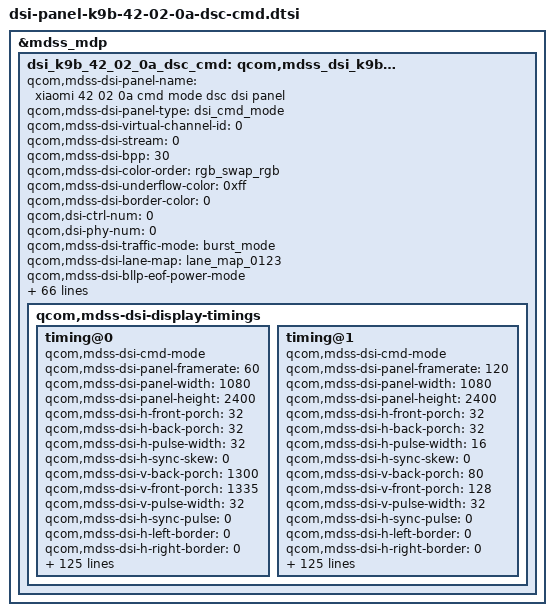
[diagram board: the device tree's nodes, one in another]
&mdss_mdp {
	dsi_k9b_42_02_0a_dsc_cmd: qcom,mdss_dsi_k9b_42_02_0a_dsc_cmd {
		qcom,mdss-dsi-panel-name = "xiaomi 42 02 0a cmd mode dsc dsi panel";
		qcom,mdss-dsi-panel-type = "dsi_cmd_mode";
		qcom,mdss-dsi-virtual-channel-id = <0>;
		qcom,mdss-dsi-stream = <0>;
		qcom,mdss-dsi-bpp = <30>;
		qcom,mdss-dsi-color-order = "rgb_swap_rgb";
		qcom,mdss-dsi-underflow-color = <0xff>;
		qcom,mdss-dsi-border-color = <0>;

		qcom,dsi-ctrl-num = <0>;
		qcom,dsi-phy-num = <0>;

		qcom,mdss-dsi-traffic-mode = "burst_mode";
		qcom,mdss-dsi-lane-map = "lane_map_0123";
		qcom,mdss-dsi-bllp-eof-power-mode;
		qcom,mdss-dsi-bllp-power-mode;
		qcom,mdss-dsi-lane-0-state;
		qcom,mdss-dsi-lane-1-state;
		qcom,mdss-dsi-lane-2-state;
		qcom,mdss-dsi-lane-3-state;
		qcom,mdss-dsi-dma-trigger = "trigger_sw";
		qcom,mdss-dsi-mdp-trigger = "none";
		qcom,mdss-dsi-reset-sequence =  <1 11>, <0 1>, <1 11>;
		qcom,mdss-pan-physical-width-dimension = <683>;
		qcom,mdss-pan-physical-height-dimension = <1517>;
		qcom,mdss-dsi-te-pin-select = <1>;
		qcom,mdss-dsi-wr-mem-start = <0x2c>;
		qcom,mdss-dsi-wr-mem-continue = <0x3c>;
		qcom,mdss-dsi-te-dcs-command = <1>;
		qcom,mdss-dsi-te-check-enable;
		qcom,mdss-dsi-te-using-te-pin;
		qcom,mdss-dsi-tx-eot-append;
		qcom,mdss-dsi-lp11-init;

		qcom,mdss-dsi-bl-inverted-dbv;
		qcom,bl-update-flag = "delay_until_first_frame";
		qcom,mdss-dsi-panel-mode-switch;

		qcom,mdss-dsi-panel-hdr-enabled;
		qcom,mdss-dsi-panel-hdr-color-primaries = <14500 15500 32000 17000 15500 30000 8000 3000>;
		qcom,mdss-dsi-panel-peak-brightness = <4200000>;
		qcom,mdss-dsi-panel-blackness-level = <3230>;

		qcom,mdss-dsi-display-timings {
			timing@0{
				qcom,mdss-dsi-cmd-mode;
				qcom,mdss-dsi-panel-framerate = <60>;
				qcom,mdss-dsi-panel-width = <1080>;
				qcom,mdss-dsi-panel-height = <2400>;
				qcom,mdss-dsi-h-front-porch = <32>;
				qcom,mdss-dsi-h-back-porch = <32>;
				qcom,mdss-dsi-h-pulse-width = <32>;
				qcom,mdss-dsi-h-sync-skew = <0>;
				qcom,mdss-dsi-v-back-porch = <1300>;
				qcom,mdss-dsi-v-front-porch = <1335>;
				qcom,mdss-dsi-v-pulse-width = <32>;
				qcom,mdss-dsi-h-sync-pulse = <0>;
				qcom,mdss-dsi-h-left-border = <0>;
				qcom,mdss-dsi-h-right-border = <0>;
				qcom,mdss-dsi-v-top-border = <0>;
				qcom,mdss-dsi-v-bottom-border = <0>;
				qcom,mdss-dsi-panel-clockrate = <831000000>;
				qcom,mdss-dsi-panel-jitter = <0x5 0x1>;
				qcom,mdss-mdp-transfer-time-us = <14000>;
				qcom,mdss-dsi-on-command = [
					/* DSC Setting */
					15 01 00 00 00 00 02 90 01
					39 01 00 00 00 00 13 91
						A9 28 00 0C C2 00 03 1C 01 7E 00 0F 08 BB 04 3D
						10 F0
					15 01 00 00 00 00 02 03 01
					05 01 00 00 00 00 02 2C 00
					/* TE ON Setting */
					15 01 00 00 00 00 02 35 00
					/* CASET/RASET Setting */
					39 01 00 00 00 00 05 2A 00 00 04 37 /* CASET 1080 */
					39 01 00 00 00 00 05 2B 00 00 09 5F /* PASET 2400 */
					/* Dimming OFF Setting */
					15 01 00 00 00 00 02 53 20
					/* dimming 8 frame */
					39 01 00 00 00 00 06 F0 55 AA 52 08 00
					39 00 00 00 00 00 02 6F 02
					39 01 00 00 00 00 03 B2 08 08
					/* Brightness Setting Normal */
					39 01 00 00 00 00 03 51 00 00
					/* Frame Rate 60Hz */
					15 01 00 00 00 00 02 2F 01
					/* MIPI Speed = 831Mbps @osc 127.9525Mhz */
					39 01 00 00 00 00 06 F0 55 AA 52 08 01
					39 00 00 00 00 00 08 C3 94 01 8C D0 22 02 00
					39 00 00 00 00 00 02 6F 01
					39 00 00 00 00 00 04 D2 00 00 11
					39 00 00 00 00 00 02 6F 06
					39 00 00 00 00 00 02 D2 05
					//U_ELVDD discharge
					39 00 00 00 00 00 02 6F 09
					39 00 00 00 00 00 03 D2 00 00
					39 00 00 00 00 00 02 6F 0F
					39 00 00 00 00 00 02 D2 00
					// U_ELVDD/U_ELVSS FD disable , AVDD FD disable
					39 00 00 00 00 00 02 CE 00
					//cmd3: aod no black
					39 01 00 00 00 00 05 FF AA 55 A5 80
					39 00 00 00 00 00 02 6F 61
					39 00 00 00 00 00 02 F3 80
					/* Page 0 */
					39 01 00 00 00 00 06 F0 55 AA 52 08 00
					39 00 00 00 00 00 02 C0 46
					//esd normal high without mipi error
					39 00 00 00 00 00 03 BE 0E 0B
					39 00 00 00 00 00 02 6F 05
					39 00 00 00 00 00 02 BE 88
					//PMIC normal FD en
					39 00 00 00 00 00 02 6F 08
					39 00 00 00 00 00 02 B5 32
					//PMIC AOD FD disable
					39 00 00 00 00 00 02 6F 0B
					39 00 00 00 00 00 04 B5 33 23 2B
					/* local hbm */
					39 00 00 00 00 00 02 6F 29
					39 00 00 00 00 00 02 D9 00
					39 00 00 00 00 00 02 6F 01
					39 00 00 00 00 00 02 D9 80
					39 00 00 00 00 00 02 6F 07
					39 00 00 00 00 00 03 B2 07 FF
					39 00 00 00 00 00 02 6F 17
					39 00 00 00 00 00 03 B2 07 FF
					39 00 00 00 00 00 02 6F 1F
					39 01 00 00 00 00 03 B2 00 50
					39 01 00 00 00 00 06 F0 55 AA 52 08 07
					39 00 00 00 00 00 02 C0 05
					39 00 00 00 00 00 2C C1 30 0F 03 C1 0B D1 F2 AE 3F FC DC AA 3F F9 27 4A 80 00 A7 E2 79 00 1A 00 00 85 1F 33 B0 0C F5 0F E1 95 00 00 00 14 18 00 19 1F 00
					39 00 00 00 00 00 2C C2 38 0F 0D 99 02 71 F4 7A 3F F9 F8 D6 FF FD E2 02 00 00 75 80 91 00 00 20 00 19 8F 33 F0 0A D7 0F 91 E7 00 00 04 1E 18 04 23 1F 00
					39 00 00 00 00 00 2C C3 36 00 03 C1 0B D1 0D 52 00 00 00 00 3F F3 96 04 80 00 00 00 00 03 B2 00 04 1D 1F 33 B0 00 00 03 1F 95 00 00 90 14 40 90 19 47 00
					39 00 00 00 00 00 2C C4 3E 00 0D 99 02 71 0B 86 00 03 5F 48 FF FC C1 EC 00 00 00 00 00 04 1E 20 04 37 8F 33 F0 00 00 03 6F E7 00 00 94 1E 40 94 23 47 00
					39 00 00 00 00 00 2C C5 2C 00 0D 99 02 71 0B 86 3F F4 F9 BC C0 00 00 00 00 00 00 00 00 80 00 D0 90 19 3F 33 F0 00 00 0C 91 19 00 00 00 00 00 00 00 00 00
					39 00 00 00 00 00 2C C6 2C 00 03 C1 0B D1 0D 52 3F FB 3F BC 00 03 FC 18 00 00 00 00 00 90 1A 40 90 85 5F 33 30 00 00 0C E1 6B 00 00 00 00 00 00 00 00 00
					39 00 00 00 00 00 2C C7 2A 0F 03 C1 0B D1 F2 AE 00 01 9C EE 00 09 8D 5E 7F FE AB 86 0D 93 B2 40 94 1D 5F 33 3F F3 0B 00 1F 6B 00 00 00 00 00 00 00 00 00
					39 01 00 00 00 00 2C C8 2A 0F 0D 99 02 71 F4 7A 00 08 5E 62 C0 01 20 16 7F FF 0D 95 E5 84 1E D0 94 37 3F 33 FF F5 29 00 6F 19 00 00 00 00 00 00 00 00 00
					39 00 00 00 00 00 2C C9 21 00 2A 40 2B E4 00 00 3F DD 03 00 3F DC 56 C0 80 07 3E 61 00 71 B3 FA 82 1D 62 33 F0 2B 10 0F 98 96 00 00 00 00 00 00 00 00 00
					39 00 00 00 00 00 2C CA 27 00 2B 11 28 A4 00 00 00 00 00 00 3F DE A9 78 80 00 00 00 00 72 1E FA 82 84 63 33 D0 00 00 03 69 9A 00 00 00 00 00 00 00 00 00
					39 00 00 00 00 00 2C CB 2D 00 2A 40 2B 11 00 00 3F DD 57 80 80 00 00 00 00 00 00 00 00 81 B3 63 82 1C CB 33 90 00 00 0C 98 69 00 00 00 00 00 00 00 00 00
					39 00 00 00 00 00 2C CC 2B 00 29 71 29 71 00 00 00 00 00 00 80 00 00 00 7F F9 4A 9C 1F 82 1D 64 82 84 CB 33 8F D6 8F 00 67 67 00 00 00 00 00 00 00 00 00
					39 00 00 00 00 00 2C CD 2D 00 03 C1 03 C1 00 00 3F FF 17 42 00 00 00 00 80 00 00 00 00 01 FC 3F 02 1B 5E 33 50 00 00 0C E1 1F 00 00 00 00 00 00 00 00 00
					39 00 00 00 00 00 2C CE 2B 00 03 C1 03 C1 00 00 00 00 00 00 00 00 00 00 FF FF F1 E8 7F 02 1C 3F 02 3B 5E 33 5F FC 3F 00 1F 1F 00 00 00 00 00 00 00 00 00
					39 00 00 00 00 00 2C CF 21 00 03 C1 03 84 00 00 3F FF 1E C4 3F FF 26 08 00 00 0D 32 84 01 FC 1F 02 1A 3E 33 80 03 A2 0F E1 E2 00 00 00 00 00 00 00 00 00
					39 01 00 00 00 00 2C D0 27 00 03 C1 04 00 00 00 00 00 00 00 3F FF 08 00 00 00 00 00 00 02 1B 1F 02 3B 3E 33 90 00 00 03 1F E0 00 00 00 00 00 00 00 00 00
					/* Sleep Out */
					05 01 00 00 50 00 02 11 00
					/* Display On */
					05 01 00 00 00 00 02 29 00];
				qcom,mdss-dsi-off-command = [
					05 01 00 00 14 00 02 28 00
					05 01 00 00 50 00 02 10 00];
				qcom,mdss-dsi-on-command-state = "dsi_lp_mode";
				qcom,mdss-dsi-off-command-state = "dsi_lp_mode";

				qcom,mdss-dsi-timing-switch-command = [
					15 01 00 00 10 00 02 2F 01
				];
				qcom,mdss-dsi-timing-switch-command-state = "dsi_hs_mode";

				qcom,mdss-dsi-lp1-command = [
					/* Frame Rate 60Hz AOD on*/
					15 01 00 00 00 00 02 2F 01
					39 00 00 00 00 00 06 F0 55 AA 52 08 08
					39 00 00 00 00 00 02 6F 07
					39 01 00 00 00 00 05 B9 00 00 00 24
					39 01 00 00 00 00 06 F0 55 AA 52 08 00
					39 00 00 00 00 00 02 B2 08
					39 00 00 00 00 00 02 39 00
					39 01 00 00 00 00 02 65 01
				];
				qcom,mdss-dsi-lp1-commandd-state = "dsi_hs_mode";

				qcom,mdss-dsi-nolp-command = [
					39 01 00 00 00 00 06 F0 55 AA 52 08 01
					39 00 00 00 00 00 02 6F 02
					39 01 00 00 00 00 02 D2 03
					39 01 00 00 00 00 06 F0 55 AA 52 08 00
					39 00 00 00 00 00 02 B2 18
					39 00 00 00 00 00 02 65 00
					39 01 00 00 00 00 02 38 00
				];
				qcom,mdss-dsi-nolp-command-state = "dsi_hs_mode";

				qcom,compression-mode = "dsc";
				qcom,mdss-dsc-version = <0x11>;
				qcom,mdss-dsc-scr-version = <0x0>;
				qcom,mdss-dsc-slice-height = <12>;
				qcom,mdss-dsc-slice-width = <1080>;
				qcom,mdss-dsc-slice-per-pkt = <1>;
				qcom,mdss-dsc-bit-per-component = <10>;
				qcom,mdss-dsc-bit-per-pixel = <8>;
				qcom,mdss-dsc-block-prediction-enable;
			};
			timing@1{
				qcom,mdss-dsi-cmd-mode;
				qcom,mdss-dsi-panel-framerate = <120>;
				qcom,mdss-dsi-panel-width = <1080>;
				qcom,mdss-dsi-panel-height = <2400>;
				qcom,mdss-dsi-h-front-porch = <32>;
				qcom,mdss-dsi-h-back-porch = <32>;
				qcom,mdss-dsi-h-pulse-width = <16>;
				qcom,mdss-dsi-h-sync-skew = <0>;
				qcom,mdss-dsi-v-back-porch = <80>;
				qcom,mdss-dsi-v-front-porch = <128>;
				qcom,mdss-dsi-v-pulse-width = <32>;
				qcom,mdss-dsi-h-sync-pulse = <0>;
				qcom,mdss-dsi-h-left-border = <0>;
				qcom,mdss-dsi-h-right-border = <0>;
				qcom,mdss-dsi-v-top-border = <0>;
				qcom,mdss-dsi-v-bottom-border = <0>;
				qcom,mdss-dsi-panel-clockrate = <831000000>;
				qcom,mdss-dsi-panel-jitter = <0x5 0x1>;
				qcom,mdss-mdp-transfer-time-us = <8000>;
				qcom,mdss-dsi-on-command = [
					/* DSC Setting */
					15 01 00 00 00 00 02 90 01
					39 01 00 00 00 00 13 91
						A9 28 00 0C C2 00 03 1C 01 7E 00 0F 08 BB 04 3D
						10 F0
					15 01 00 00 00 00 02 03 01
					05 01 00 00 00 00 02 2C 00
					/* TE ON Setting */
					15 01 00 00 00 00 02 35 00
					/* CASET/RASET Setting */
					39 01 00 00 00 00 05 2A 00 00 04 37 /* CASET 1080 */
					39 01 00 00 00 00 05 2B 00 00 09 5F /* PASET 2400 */
					/* Dimming Off seting */
					15 01 00 00 00 00 02 53 20
					/* dimming 8 frame */
					39 01 00 00 00 00 06 F0 55 AA 52 08 00
					39 00 00 00 00 00 02 6F 02
					39 01 00 00 00 00 03 B2 08 08
					/* Brightness Setting Normal */
					39 01 00 00 00 00 03 51 00 00
					/* Frame Rate 120Hz */
					15 01 00 00 00 00 02 2F 02
					/* MIPI Speed = 831Mbps @osc 127.9525Mhz */
					39 01 00 00 00 00 06 F0 55 AA 52 08 01
					39 00 00 00 00 00 08 C3 94 01 8C D0 22 02 00
					39 00 00 00 00 00 02 6F 01
					39 00 00 00 00 00 04 D2 00 00 11
					39 00 00 00 00 00 02 6F 06
					39 00 00 00 00 00 02 D2 05
					//U_ELVDD discharge
					39 00 00 00 00 00 02 6F 09
					39 00 00 00 00 00 03 D2 00 00
					39 00 00 00 00 00 02 6F 0F
					39 00 00 00 00 00 02 D2 00
					// U_ELVDD/U_ELVSS FD disable , AVDD FD disable
					39 00 00 00 00 00 02 CE 00
					//cmd3: aod no black
					39 01 00 00 00 00 05 FF AA 55 A5 80
					39 00 00 00 00 00 02 6F 61
					39 00 00 00 00 00 02 F3 80
					/* Page 0 */
					39 01 00 00 00 00 06 F0 55 AA 52 08 00
					39 00 00 00 00 00 02 C0 46
					//esd normal high without mipi error
					39 00 00 00 00 00 03 BE 0E 0B
					39 00 00 00 00 00 02 6F 05
					39 00 00 00 00 00 02 BE 88
					//PMIC normal FD en
					39 00 00 00 00 00 02 6F 08
					39 00 00 00 00 00 02 B5 32
					//PMIC AOD FD disable
					39 00 00 00 00 00 02 6F 0B
					39 00 00 00 00 00 04 B5 33 23 2B
					/* local hbm */
					39 00 00 00 00 00 02 6F 29
					39 00 00 00 00 00 02 D9 00
					39 00 00 00 00 00 02 6F 01
					39 00 00 00 00 00 02 D9 80
					39 00 00 00 00 00 02 6F 07
					39 00 00 00 00 00 03 B2 07 FF
					39 00 00 00 00 00 02 6F 17
					39 00 00 00 00 00 03 B2 07 FF
					39 00 00 00 00 00 02 6F 1F
					39 01 00 00 00 00 03 B2 00 50
					39 01 00 00 00 00 06 F0 55 AA 52 08 07
					39 00 00 00 00 00 02 C0 05
					39 00 00 00 00 00 2C C1 30 0F 03 C1 0B D1 F2 AE 3F FC DC AA 3F F9 27 4A 80 00 A7 E2 79 00 1A 00 00 85 1F 33 B0 0C F5 0F E1 95 00 00 00 14 18 00 19 1F 00
					39 00 00 00 00 00 2C C2 38 0F 0D 99 02 71 F4 7A 3F F9 F8 D6 FF FD E2 02 00 00 75 80 91 00 00 20 00 19 8F 33 F0 0A D7 0F 91 E7 00 00 04 1E 18 04 23 1F 00
					39 00 00 00 00 00 2C C3 36 00 03 C1 0B D1 0D 52 00 00 00 00 3F F3 96 04 80 00 00 00 00 03 B2 00 04 1D 1F 33 B0 00 00 03 1F 95 00 00 90 14 40 90 19 47 00
					39 00 00 00 00 00 2C C4 3E 00 0D 99 02 71 0B 86 00 03 5F 48 FF FC C1 EC 00 00 00 00 00 04 1E 20 04 37 8F 33 F0 00 00 03 6F E7 00 00 94 1E 40 94 23 47 00
					39 00 00 00 00 00 2C C5 2C 00 0D 99 02 71 0B 86 3F F4 F9 BC C0 00 00 00 00 00 00 00 00 80 00 D0 90 19 3F 33 F0 00 00 0C 91 19 00 00 00 00 00 00 00 00 00
					39 00 00 00 00 00 2C C6 2C 00 03 C1 0B D1 0D 52 3F FB 3F BC 00 03 FC 18 00 00 00 00 00 90 1A 40 90 85 5F 33 30 00 00 0C E1 6B 00 00 00 00 00 00 00 00 00
					39 00 00 00 00 00 2C C7 2A 0F 03 C1 0B D1 F2 AE 00 01 9C EE 00 09 8D 5E 7F FE AB 86 0D 93 B2 40 94 1D 5F 33 3F F3 0B 00 1F 6B 00 00 00 00 00 00 00 00 00
					39 01 00 00 00 00 2C C8 2A 0F 0D 99 02 71 F4 7A 00 08 5E 62 C0 01 20 16 7F FF 0D 95 E5 84 1E D0 94 37 3F 33 FF F5 29 00 6F 19 00 00 00 00 00 00 00 00 00
					39 00 00 00 00 00 2C C9 21 00 2A 40 2B E4 00 00 3F DD 03 00 3F DC 56 C0 80 07 3E 61 00 71 B3 FA 82 1D 62 33 F0 2B 10 0F 98 96 00 00 00 00 00 00 00 00 00
					39 00 00 00 00 00 2C CA 27 00 2B 11 28 A4 00 00 00 00 00 00 3F DE A9 78 80 00 00 00 00 72 1E FA 82 84 63 33 D0 00 00 03 69 9A 00 00 00 00 00 00 00 00 00
					39 00 00 00 00 00 2C CB 2D 00 2A 40 2B 11 00 00 3F DD 57 80 80 00 00 00 00 00 00 00 00 81 B3 63 82 1C CB 33 90 00 00 0C 98 69 00 00 00 00 00 00 00 00 00
					39 00 00 00 00 00 2C CC 2B 00 29 71 29 71 00 00 00 00 00 00 80 00 00 00 7F F9 4A 9C 1F 82 1D 64 82 84 CB 33 8F D6 8F 00 67 67 00 00 00 00 00 00 00 00 00
					39 00 00 00 00 00 2C CD 2D 00 03 C1 03 C1 00 00 3F FF 17 42 00 00 00 00 80 00 00 00 00 01 FC 3F 02 1B 5E 33 50 00 00 0C E1 1F 00 00 00 00 00 00 00 00 00
					39 00 00 00 00 00 2C CE 2B 00 03 C1 03 C1 00 00 00 00 00 00 00 00 00 00 FF FF F1 E8 7F 02 1C 3F 02 3B 5E 33 5F FC 3F 00 1F 1F 00 00 00 00 00 00 00 00 00
					39 00 00 00 00 00 2C CF 21 00 03 C1 03 84 00 00 3F FF 1E C4 3F FF 26 08 00 00 0D 32 84 01 FC 1F 02 1A 3E 33 80 03 A2 0F E1 E2 00 00 00 00 00 00 00 00 00
					39 01 00 00 00 00 2C D0 27 00 03 C1 04 00 00 00 00 00 00 00 3F FF 08 00 00 00 00 00 00 02 1B 1F 02 3B 3E 33 90 00 00 03 1F E0 00 00 00 00 00 00 00 00 00
					/* Sleep Out */
					05 01 00 00 50 00 02 11 00
					/* Display On */
					05 01 00 00 00 00 02 29 00];
				qcom,mdss-dsi-off-command = [
					05 01 00 00 14 00 02 28 00
					05 01 00 00 50 00 02 10 00];
				qcom,mdss-dsi-on-command-state = "dsi_lp_mode";
				qcom,mdss-dsi-off-command-state = "dsi_lp_mode";

				qcom,mdss-dsi-timing-switch-command = [
					15 01 00 00 10 00 02 2F 02
				];
				qcom,mdss-dsi-timing-switch-command-state = "dsi_hs_mode";

				qcom,mdss-dsi-lp1-command = [
					/* Frame Rate 120Hz AOD on*/
					15 01 00 00 00 00 02 2F 01
					39 00 00 00 00 00 06 F0 55 AA 52 08 08
					39 00 00 00 00 00 02 6F 07
					39 01 00 00 00 00 05 B9 00 00 00 24
					39 01 00 00 00 00 06 F0 55 AA 52 08 00
					39 00 00 00 00 00 02 B2 08
					39 00 00 00 00 00 02 39 00
					39 01 00 00 00 00 02 65 01
				];
				qcom,mdss-dsi-lp1-commandd-state = "dsi_hs_mode";

				qcom,mdss-dsi-nolp-command = [
					39 01 00 00 00 00 06 F0 55 AA 52 08 01
					39 00 00 00 00 00 02 6F 02
					39 01 00 00 00 00 02 D2 03
					/* AOD off */
					39 01 00 00 00 00 06 F0 55 AA 52 08 00
					39 00 00 00 00 00 02 B2 18
					39 00 00 00 00 00 02 65 00
					39 01 00 00 00 00 02 38 00
					39 01 00 00 00 00 02 2F 02
				];
				qcom,mdss-dsi-nolp-command-state = "dsi_hs_mode";

				qcom,compression-mode = "dsc";
				qcom,mdss-dsc-version = <0x11>;
				qcom,mdss-dsc-scr-version = <0x0>;
				qcom,mdss-dsc-slice-height = <12>;
				qcom,mdss-dsc-slice-width = <1080>;
				qcom,mdss-dsc-slice-per-pkt = <1>;
				qcom,mdss-dsc-bit-per-component = <10>;
				qcom,mdss-dsc-bit-per-pixel = <8>;
				qcom,mdss-dsc-block-prediction-enable;
			};
		};
	};
};

&dsi_k9b_42_02_0a_dsc_cmd {
	mi,panel-id = <0x004B3942 0x00420200>;
	mi,hbm-51-ctl-flag;
	mi,bl-51ctl-32bit-flag;
	mi,aod-bl-51ctl-flag;
	mi,aod-brightness = <0x155 0x0FFF>;
	mi,hbm-off-51-index = <0>;
	mi,hbm-fod-off-51-index = <1>;
	mi,hbm-bl-min-level = <1>;
	mi,hbm-bl-max-level = <2047>;
	mi,max-brightness-clone = <4095>;
	mi,thermal-dimming-flag;

	mi,local-hbm-enabled;
	mi,local-hbm-off-to-hbm-51-index = <1>;
	mi,local-hbm-off-to-normal-51-index = <1>;
	mi,local-hbm-on-87-index = <5>;
	mi,local-hbm-hlpm-on-87-index = <10>;
	mi,doze-hbm-dbv-level = <245>;
	mi,doze-lbm-dbv-level = <20>;
	mi,fod-low-brightness-clone-threshold = <38>;
	mi,fod-low-brightness-lux-threshold = <1>;

	mi,flatmode-update-flag;
	mi,flatmode-on-b9-index = <3>;

	mi,lhbm-update-flag;

	/* IRQF_ONESHOT | IRQF_TRIGGER_FALLING */
	mi,esd-err-irq-gpio = <&tlmm 3 0x2002>;

	mi,panel-aod-to-off-command-need-enabled;

	mi,panel-on-dimming-delay = <120>;

	qcom,esd-check-enabled;
	qcom,esd-aod-check-enabled;
	qcom,mdss-dsi-panel-status-check-mode = "reg_read";
	qcom,mdss-dsi-panel-status-offset-command = [
		39 01 00 00 00 00 05 FF AA 55 A5 81
		15 01 00 00 00 00 02 6F 0F];
	qcom,mdss-dsi-panel-status-command = [06 01 00 00 00 00 01 FA];
	qcom,mdss-dsi-panel-status-command-state = "dsi_lp_mode";
	qcom,mdss-dsi-panel-status-offset-command-state = "dsi_lp_mode";
	qcom,mdss-dsi-panel-status-value = <0x00>;
	qcom,mdss-dsi-panel-status-read-length = <1>;

	qcom,mdss-dsi-display-timings {
		timing@0{ /* 60hz */
			mi,mdss-dsc-panel-id = <0x004B3942 0x00420200>;
			mi,mdss-dsi-dimmingon-command = [15 01 00 00 00 00 02 53 28];
			mi,mdss-dsi-dimmingon-command-state = "dsi_hs_mode";
			mi,mdss-dsi-dimmingoff-command = [15 01 00 00 00 00 02 53 20];
			mi,mdss-dsi-dimmingoff-command-state = "dsi_hs_mode";

			mi,mdss-dsi-hbm-on-command = [39 01 00 00 00 00 03 51 0F FF];
			mi,mdss-dsi-hbm-on-command-state = "dsi_hs_mode";
			mi,mdss-dsi-hbm-off-command = [39 01 00 00 00 00 03 51 07 FF];
			mi,mdss-dsi-hbm-off-command-state = "dsi_hs_mode";

			mi,mdss-dsi-doze-hbm-command = [
				39 01 00 00 00 00 06 F0 55 AA 52 08 00
				39 00 00 00 00 00 02 B2 08
				39 00 00 00 00 00 05 51 00 F5 0F FF
				39 00 00 00 00 00 02 39 00
				39 01 00 00 00 00 02 65 01
			];
			mi,mdss-dsi-doze-hbm-command-state = "dsi_hs_mode";
			mi,mdss-dsi-doze-lbm-command = [
				39 01 00 00 00 00 06 F0 55 AA 52 08 00
				39 00 00 00 00 00 02 B2 08
				39 00 00 00 00 00 05 51 00 14 01 55
				39 00 00 00 00 00 02 39 00
				39 01 00 00 00 00 02 65 01
			];
			mi,mdss-dsi-doze-lbm-command-state = "dsi_hs_mode";

			mi,mdss-dsi-doze-hbm-nolp-command = [
				/* AOD off */
				39 01 00 00 00 00 06 F0 55 AA 52 08 00
				39 00 00 00 00 00 02 B2 18
				39 00 00 00 00 00 05 51 00 F5 0F FF
				39 00 00 00 00 00 02 65 00
				39 01 00 00 07 00 02 38 00
				39 01 00 00 00 00 06 F0 55 AA 52 08 01
				39 01 00 00 1B 00 05 BA 10 1A 10 1A
				39 01 00 00 00 00 05 BA 10 10 10 10
			];
			mi,mdss-dsi-doze-hbm-nolp-command-state = "dsi_hs_mode";
			mi,mdss-dsi-doze-lbm-nolp-command = [
				/* AOD off */
				39 01 00 00 00 00 06 F0 55 AA 52 08 00
				39 00 00 00 00 00 02 B2 18
				39 00 00 00 00 00 05 51 00 14 01 55
				39 00 00 00 00 00 02 65 00
				39 01 00 00 07 00 02 38 00
				39 01 00 00 00 00 06 F0 55 AA 52 08 01
				39 01 00 00 1B 00 05 BA 10 1A 10 1A
				39 01 00 00 00 00 05 BA 10 10 10 10
			];
			mi,mdss-dsi-doze-lbm-nolp-command-state = "dsi_hs_mode";

			mi,mdss-dsi-hbm-fod-on-command = [
				15 01 00 00 00 00 02 53 20
				39 00 00 00 00 00 03 51 0F FF
				39 00 00 00 00 00 02 6F 02
				39 01 00 00 00 00 02 87 04
			];
			mi,mdss-dsi-hbm-fod-on-command-state = "dsi_hs_mode";
			mi,mdss-dsi-hbm-fod-off-command = [
				15 01 00 00 00 00 02 53 20
				39 00 00 00 00 00 03 51 07 FF
				39 00 00 00 00 00 02 6F 02
				39 01 00 00 00 00 02 87 04
			];
			mi,mdss-dsi-hbm-fod-off-command-state = "dsi_hs_mode";

			mi,mdss-dsi-local-hbm-normal-white-1000nit-command = [
				39 01 00 00 00 00 06 F0 55 AA 52 08 02
				39 00 00 00 00 00 02 6F 08
				39 00 00 00 00 00 07 D0 0B 07 09 7B 0C 1D
				39 00 00 00 00 00 02 53 20
				39 00 00 00 00 00 05 88 02 1C 08 63
				39 00 00 00 00 00 03 87 0F FF
				39 00 00 00 00 00 03 51 07 FF
				39 00 00 00 00 00 02 6F 02
				39 01 00 00 21 00 02 87 05
			];
			mi,mdss-dsi-local-hbm-normal-white-1000nit-command-state = "dsi_hs_mode";

			mi,mdss-dsi-local-hbm-hlpm-white-1000nit-command = [
				/* AOD off */
				39 01 00 00 00 00 06 F0 55 AA 52 08 00
				39 00 00 00 00 00 02 B2 18
				39 00 00 00 00 00 02 65 00
				39 01 00 00 22 00 02 38 00
				/* 60HZ */
				15 01 00 00 00 00 02 2F 01
				/* Local HBM setting*/
				39 00 00 00 00 00 06 F0 55 AA 52 08 02
				39 00 00 00 00 00 02 6F 08
				39 00 00 00 00 00 07 D0 0B 07 09 7B 0C 1D
				39 00 00 00 00 00 02 53 20
				39 00 00 00 00 00 05 88 02 1C 08 63
				39 00 00 00 00 00 03 87 0F FF
				39 00 00 00 00 00 03 51 07 FF
				39 00 00 00 00 00 02 6F 02
				39 01 00 00 21 00 02 87 05
			];
			mi,mdss-dsi-local-hbm-hlpm-white-1000nit-command-state = "dsi_hs_mode";

			mi,mdss-dsi-local-hbm-normal-white-110nit-command = [
				39 01 00 00 00 00 06 F0 55 AA 52 08 02
				39 00 00 00 00 00 02 6F 08
				39 00 00 00 00 00 07 D0 07 62 06 74 07 F7
				39 00 00 00 00 00 02 53 20
				39 00 00 00 00 00 05 88 02 1C 08 63
				39 00 00 00 00 00 03 87 0F FF
				39 00 00 00 00 00 03 51 07 FF
				39 00 00 00 00 00 02 6F 02
				39 01 00 00 21 00 02 87 05
			];
			mi,mdss-dsi-local-hbm-normal-white-110nit-command-state = "dsi_hs_mode";

			mi,mdss-dsi-local-hbm-hlpm-white-110nit-command = [
				/* AOD off */
				39 01 00 00 00 00 06 F0 55 AA 52 08 00
				39 00 00 00 00 00 02 B2 18
				39 00 00 00 00 00 02 65 00
				39 01 00 00 22 00 02 38 00
				/* 60HZ */
				15 01 00 00 00 00 02 2F 01
				/* Local HBM setting*/
				39 01 00 00 00 00 06 F0 55 AA 52 08 02
				39 00 00 00 00 00 02 6F 08
				39 00 00 00 00 00 07 D0 07 62 06 74 07 F7
				39 00 00 00 00 00 02 53 20
				39 00 00 00 00 00 05 88 02 1C 08 63
				39 00 00 00 00 00 03 87 0F FF
				39 00 00 00 00 00 03 51 07 FF
				39 00 00 00 00 00 02 6F 02
				39 01 00 00 21 00 02 87 05
			];
			mi,mdss-dsi-local-hbm-hlpm-white-110nit-command-state = "dsi_hs_mode";

			mi,mdss-dsi-local-hbm-normal-green-500nit-command = [
				39 01 00 00 00 00 06 F0 55 AA 52 08 02
				39 00 00 00 00 00 02 6F 08
				39 00 00 00 00 00 07 D0 00 00 09 40 00 00
				39 00 00 00 00 00 02 53 20
				39 00 00 00 00 00 05 88 02 1C 08 63
				39 00 00 00 00 00 03 87 0F FF
				39 00 00 00 00 00 03 51 07 FF
				39 00 00 00 00 00 02 6F 02
				39 01 00 00 21 00 02 87 05
			];
			mi,mdss-dsi-local-hbm-normal-green-500nit-command-state = "dsi_hs_mode";

			mi,mdss-dsi-local-hbm-off-to-normal-command = [
				15 01 00 00 00 00 02 53 20
				39 00 00 00 00 00 03 51 00 00
				39 00 00 00 00 00 02 6F 02
				39 01 00 00 00 00 02 87 04
			];
			mi,mdss-dsi-local-hbm-off-to-normal-command-state = "dsi_hs_mode";

			mi,mdss-dsi-local-hbm-off-to-hbm-command = [
				15 01 00 00 00 00 02 53 20
				39 00 00 00 00 00 03 51 00 00
				39 00 00 00 00 00 02 6F 02
				39 01 00 00 00 00 02 87 04
			];
			mi,mdss-dsi-local-hbm-off-to-hbm-command-state = "dsi_hs_mode";

			mi,mdss-dsi-local-hbm-off-to-hlpm-command = [
				15 01 00 00 00 00 02 53 20
				/* local hbm off */
				39 00 00 00 00 00 03 51 00 00
				39 00 00 00 00 00 02 6F 02
				39 01 00 00 00 00 02 87 04
				/* aod hbm */
				39 01 00 00 00 00 02 2F 01
				39 00 00 00 00 00 06 F0 55 AA 52 08 08
				39 00 00 00 00 00 02 6F 07
				39 01 00 00 00 00 05 B9 00 00 00 24
				39 01 00 00 00 00 06 F0 55 AA 52 08 00
				39 00 00 00 00 00 02 B2 08
				39 00 00 00 00 00 05 51 00 F5 0F FF
				39 00 00 00 00 00 02 39 00
				39 01 00 00 00 00 02 65 01
			];
			mi,mdss-dsi-local-hbm-off-to-hlpm-command-state = "dsi_hs_mode";

			mi,mdss-dsi-local-hbm-off-to-llpm-command = [
				15 01 00 00 00 00 02 53 20
				/* local hbm off */
				39 00 00 00 00 00 03 51 00 00
				39 00 00 00 00 00 02 6F 02
				39 01 00 00 00 00 02 87 04
				/* aod lbm */
				39 01 00 00 00 00 02 2F 01
				39 00 00 00 00 00 06 F0 55 AA 52 08 08
				39 00 00 00 00 00 02 6F 07
				39 01 00 00 00 00 05 B9 00 00 00 24
				39 00 00 00 00 00 06 F0 55 AA 52 08 00
				39 00 00 00 00 00 02 B2 08
				39 00 00 00 00 00 05 51 00 14 01 55
				39 00 00 00 00 00 02 39 00
				39 01 00 00 00 00 02 65 01
			];
			mi,mdss-dsi-local-hbm-off-to-llpm-command-state = "dsi_hs_mode";

			mi,mdss-dsi-flat-mode-read-pre-command = [
				/* set page 0 */
				39 01 00 00 00 00 06 F0 55 AA 52 08 00
				/* set register offset */
				15 01 00 00 00 00 02 6F 3F];
			mi,mdss-dsi-flat-mode-read-pre-command-state = "dsi_lp_mode";
			mi,mdss-dsi-flat-mode-on-command = [
				/* GIR ON , 60Hz */
				39 00 00 00 00 00 02 2F 03
				/* set page 8 */
				39 00 00 00 00 00 06 F0 55 AA 52 08 08
				39 00 00 00 00 00 02 6F 07
				/* must to use read flatmode parameter to update */
				39 01 00 00 00 00 05 B9 00 00 00 00
			];
			mi,mdss-dsi-flat-mode-on-command-state = "dsi_hs_mode";
			mi,mdss-dsi-flat-mode-off-command = [
				/* GIR Off , 60Hz */
				39 00 00 00 00 00 02 2F 01
				39 00 00 00 00 00 06 F0 55 AA 52 08 08
				39 00 00 00 00 00 02 6F 07
				39 01 00 00 00 00 05 B9 00 00 00 24
			];
			mi,mdss-dsi-flat-mode-off-command-state = "dsi_hs_mode";
			mi,mdss-dsi-timing-switch-gir-command = [
				/* Frame Rate 60Hz GIR ON */
				39 01 00 00 09 00 02 2F 03
			];
			mi,mdss-dsi-timing-switch-gir-command-state = "dsi_hs_mode";

			mi,mdss-dsi-pre-doze-to-off-command = [
				39 01 00 00 00 00 06 F0 55 AA 52 08 01
				15 01 00 00 00 00 02 CE 0C];
			mi,mdss-dsi-pre-doze-to-off-command-state = "dsi_hs_mode";
		};
		timing@1{ /* 120hz */
			mi,mdss-dsc-panel-id = <0x004B3942 0x00420200>;
			mi,mdss-dsi-dimmingon-command = [15 01 00 00 00 00 02 53 28];
			mi,mdss-dsi-dimmingon-command-state = "dsi_hs_mode";
			mi,mdss-dsi-dimmingoff-command = [15 01 00 00 00 00 02 53 20];
			mi,mdss-dsi-dimmingoff-command-state = "dsi_hs_mode";

			mi,mdss-dsi-hbm-on-command = [39 01 00 00 00 00 03 51 0F FF];
			mi,mdss-dsi-hbm-on-command-state = "dsi_hs_mode";
			mi,mdss-dsi-hbm-off-command = [39 01 00 00 00 00 03 51 07 FF];
			mi,mdss-dsi-hbm-off-command-state = "dsi_hs_mode";

			mi,mdss-dsi-doze-hbm-command = [
				/* 60HZ */
				39 01 00 00 00 00 02 2F 01
				39 00 00 00 00 00 06 F0 55 AA 52 08 08
				39 00 00 00 00 00 02 6F 07
				39 01 00 00 00 00 05 B9 00 00 00 24
				39 01 00 00 00 00 06 F0 55 AA 52 08 00
				39 00 00 00 00 00 02 B2 08
				39 00 00 00 00 00 05 51 00 F5 0F FF
				39 00 00 00 00 00 02 39 00
				39 01 00 00 00 00 02 65 01
			];
			mi,mdss-dsi-doze-hbm-command-state = "dsi_hs_mode";
			mi,mdss-dsi-doze-lbm-command = [
				/* Frame Rate 60Hz */
				15 01 00 00 00 00 02 2F 01
				39 00 00 00 00 00 06 F0 55 AA 52 08 08
				39 00 00 00 00 00 02 6F 07
				39 01 00 00 00 00 05 B9 00 00 00 24
				39 01 00 00 00 00 06 F0 55 AA 52 08 00
				39 00 00 00 00 00 02 B2 08
				39 00 00 00 00 00 05 51 00 14 01 55
				39 00 00 00 00 00 02 39 00
				39 01 00 00 00 00 02 65 01
			];
			mi,mdss-dsi-doze-lbm-command-state = "dsi_hs_mode";

			mi,mdss-dsi-doze-hbm-nolp-command = [
				/* AOD off */
				39 01 00 00 00 00 06 F0 55 AA 52 08 00
				39 00 00 00 00 00 02 B2 18
				39 00 00 00 00 00 05 51 00 F5 0F FF
				39 00 00 00 00 00 02 65 00
				39 01 00 00 07 00 02 38 00
				39 01 00 00 00 00 06 F0 55 AA 52 08 01
				39 01 00 00 1B 00 05 BA 10 1A 10 1A
				39 01 00 00 00 00 05 BA 10 10 10 10
				/* Frame Rate 120Hz */
				15 01 00 00 00 00 02 2F 02
			];
			mi,mdss-dsi-doze-hbm-nolp-command-state = "dsi_hs_mode";
			mi,mdss-dsi-doze-lbm-nolp-command = [
				/* AOD off */
				39 01 00 00 00 00 06 F0 55 AA 52 08 00
				39 00 00 00 00 00 02 B2 18
				39 00 00 00 00 00 05 51 00 14 01 55
				39 00 00 00 00 00 02 65 00
				39 01 00 00 07 00 02 38 00
				39 01 00 00 00 00 06 F0 55 AA 52 08 01
				39 01 00 00 1B 00 05 BA 10 1A 10 1A
				39 01 00 00 00 00 05 BA 10 10 10 10
				/* Frame Rate 120Hz */
				15 01 00 00 00 00 02 2F 02
			];
			mi,mdss-dsi-doze-lbm-nolp-command-state = "dsi_hs_mode";

			mi,mdss-dsi-hbm-fod-on-command = [
				15 01 00 00 00 00 02 53 20
				39 00 00 00 00 00 03 51 0F FF
				39 00 00 00 00 00 02 6F 02
				39 01 00 00 00 00 02 87 04
			];
			mi,mdss-dsi-hbm-fod-on-command-state = "dsi_hs_mode";
			mi,mdss-dsi-hbm-fod-off-command = [
				15 01 00 00 00 00 02 53 20
				39 00 00 00 00 00 03 51 07 FF
				39 00 00 00 00 00 02 6F 02
				39 01 00 00 00 00 02 87 04
			];
			mi,mdss-dsi-hbm-fod-off-command-state = "dsi_hs_mode";

			mi,mdss-dsi-local-hbm-normal-white-1000nit-command = [
				39 01 00 00 00 00 06 F0 55 AA 52 08 02
				39 00 00 00 00 00 02 6F 08
				39 00 00 00 00 00 07 D0 0B 07 09 7B 0C 1D
				39 00 00 00 00 00 02 53 20
				39 00 00 00 00 00 05 88 02 1C 08 63
				39 00 00 00 00 00 03 87 0F FF
				39 00 00 00 00 00 03 51 07 FF
				39 00 00 00 00 00 02 6F 02
				39 01 00 00 11 00 02 87 05
			];
			mi,mdss-dsi-local-hbm-normal-white-1000nit-command-state = "dsi_hs_mode";

			mi,mdss-dsi-local-hbm-hlpm-white-1000nit-command = [
				/* AOD off */
				39 01 00 00 00 00 06 F0 55 AA 52 08 00
				39 00 00 00 00 00 02 B2 18
				39 00 00 00 00 00 02 65 00
				39 01 00 00 22 00 02 38 00
				/* 120HZ */
				39 01 00 00 00 00 02 2F 02
				/* Local HBM setting*/
				39 01 00 00 00 00 06 F0 55 AA 52 08 02
				39 00 00 00 00 00 02 6F 08
				39 00 00 00 00 00 07 D0 0B 07 09 7B 0C 1D
				39 00 00 00 00 00 02 53 20
				39 00 00 00 00 00 05 88 02 1C 08 63
				39 00 00 00 00 00 03 87 0F FF
				39 00 00 00 00 00 03 51 07 FF
				39 00 00 00 00 00 02 6F 02
				39 01 00 00 11 00 02 87 05
			];
			mi,mdss-dsi-local-hbm-hlpm-white-1000nit-command-state = "dsi_hs_mode";

			mi,mdss-dsi-local-hbm-normal-white-110nit-command = [
				39 01 00 00 00 00 06 F0 55 AA 52 08 02
				39 00 00 00 00 00 02 6F 08
				39 00 00 00 00 00 07 D0 07 62 06 74 07 F7
				39 00 00 00 00 00 02 53 20
				39 00 00 00 00 00 05 88 02 1C 08 63
				39 00 00 00 00 00 03 87 0F FF
				39 00 00 00 00 00 03 51 07 FF
				39 00 00 00 00 00 02 6F 02
				39 01 00 00 11 00 02 87 05
			];
			mi,mdss-dsi-local-hbm-normal-white-110nit-command-state = "dsi_hs_mode";

			mi,mdss-dsi-local-hbm-hlpm-white-110nit-command = [
				/* AOD off */
				39 01 00 00 00 00 06 F0 55 AA 52 08 00
				39 00 00 00 00 00 02 B2 18
				39 00 00 00 00 00 02 65 00
				39 01 00 00 22 00 02 38 00
				/* 120HZ */
				39 01 00 00 00 00 02 2F 02
				/* Local HBM setting*/
				39 01 00 00 00 00 06 F0 55 AA 52 08 02
				39 00 00 00 00 00 02 6F 08
				39 00 00 00 00 00 07 D0 07 62 06 74 07 F7
				39 00 00 00 00 00 02 53 20
				39 00 00 00 00 00 05 88 02 1C 08 63
				39 00 00 00 00 00 03 87 0F FF
				39 00 00 00 00 00 03 51 07 FF
				39 00 00 00 00 00 02 6F 02
				39 01 00 00 11 00 02 87 05
			];
			mi,mdss-dsi-local-hbm-hlpm-white-110nit-command-state = "dsi_hs_mode";

			mi,mdss-dsi-local-hbm-normal-green-500nit-command = [
				39 01 00 00 00 00 06 F0 55 AA 52 08 02
				39 00 00 00 00 00 02 6F 08
				39 00 00 00 00 00 07 D0 00 00 09 40 00 00
				39 00 00 00 00 00 02 53 20
				39 00 00 00 00 00 05 88 02 1C 08 63
				39 00 00 00 00 00 03 87 0F FF
				39 00 00 00 00 00 03 51 07 FF
				39 00 00 00 00 00 02 6F 02
				39 01 00 00 11 00 02 87 05
			];
			mi,mdss-dsi-local-hbm-normal-green-500nit-command-state = "dsi_hs_mode";

			mi,mdss-dsi-local-hbm-off-to-normal-command = [
				39 01 00 00 00 00 02 53 20
				39 00 00 00 00 00 03 51 00 00
				39 00 00 00 00 00 02 6F 02
				39 01 00 00 00 00 02 87 04
			];
			mi,mdss-dsi-local-hbm-off-to-normal-command-state = "dsi_hs_mode";

			mi,mdss-dsi-local-hbm-off-to-hbm-command = [
				39 01 00 00 00 00 02 53 20
				39 00 00 00 00 00 03 51 00 00
				39 00 00 00 00 00 02 6F 02
				39 01 00 00 00 00 02 87 04
			];
			mi,mdss-dsi-local-hbm-off-to-hbm-command-state = "dsi_hs_mode";

			mi,mdss-dsi-local-hbm-off-to-hlpm-command = [
				39 01 00 00 00 00 02 53 20
				/* local hbm off */
				39 00 00 00 00 00 03 51 00 00
				39 00 00 00 00 00 02 6F 02
				39 01 00 00 00 00 02 87 04
				/* aod hbm */
				39 01 00 00 00 00 02 2F 01
				39 00 00 00 00 00 06 F0 55 AA 52 08 08
				39 00 00 00 00 00 02 6F 07
				39 01 00 00 00 00 05 B9 00 00 00 24
				39 01 00 00 00 00 06 F0 55 AA 52 08 00
				39 00 00 00 00 00 02 B2 08
				39 00 00 00 00 00 05 51 00 F5 0F FF
				39 00 00 00 00 00 02 39 00
				39 01 00 00 00 00 02 65 01
			];
			mi,mdss-dsi-local-hbm-off-to-hlpm-command-state = "dsi_hs_mode";

			mi,mdss-dsi-local-hbm-off-to-llpm-command = [
				15 01 00 00 00 00 02 53 20
				/* local hbm off */
				39 00 00 00 00 00 03 51 00 00
				39 00 00 00 00 00 02 6F 02
				39 01 00 00 00 00 02 87 04
				/* aod lbm */
				39 01 00 00 00 00 02 2F 01
				39 00 00 00 00 00 06 F0 55 AA 52 08 08
				39 00 00 00 00 00 02 6F 07
				39 01 00 00 00 00 05 B9 00 00 00 24
				39 00 00 00 00 00 06 F0 55 AA 52 08 00
				39 00 00 00 00 00 02 B2 08
				39 00 00 00 00 00 05 51 00 14 01 55
				39 00 00 00 00 00 02 39 00
				39 01 00 00 00 00 02 65 01
			];
			mi,mdss-dsi-local-hbm-off-to-llpm-command-state = "dsi_hs_mode";

			mi,mdss-dsi-flat-mode-read-pre-command = [
				/* set page 0 */
				39 01 00 00 00 00 06 F0 55 AA 52 08 00
				/* set register offset */
				15 01 00 00 00 00 02 6F 3F];
			mi,mdss-dsi-flat-mode-read-pre-command-state = "dsi_lp_mode";
			mi,mdss-dsi-flat-mode-on-command = [
				/* GIR ON , 120Hz */
				39 00 00 00 00 00 02 2F 04
				/* set page 8 */
				39 00 00 00 00 00 06 F0 55 AA 52 08 08
				39 00 00 00 00 00 02 6F 07
				/* must to use read flatmode parameter to update */
				39 01 00 00 00 00 05 B9 00 00 00 00
			];
			mi,mdss-dsi-flat-mode-on-command-state = "dsi_hs_mode";
			mi,mdss-dsi-flat-mode-off-command = [
				/* GIR Off , 120Hz */
				39 00 00 00 00 00 02 2F 02
				39 00 00 00 00 00 06 F0 55 AA 52 08 08
				39 00 00 00 00 00 02 6F 07
				39 01 00 00 00 00 05 B9 00 00 00 24
			];
			mi,mdss-dsi-flat-mode-off-command-state = "dsi_hs_mode";
			mi,mdss-dsi-timing-switch-gir-command = [
				/* Frame Rate 120Hz GIR ON */
				39 01 00 00 09 00 02 2F 04
			];
			mi,mdss-dsi-timing-switch-gir-command-state = "dsi_hs_mode";

			mi,mdss-dsi-pre-doze-to-off-command = [
				39 01 00 00 00 00 06 F0 55 AA 52 08 01
				15 01 00 00 00 00 02 CE 0C];
			mi,mdss-dsi-pre-doze-to-off-command-state = "dsi_hs_mode";
		};
	};
};
